# psc3_p8_ppca register map
Vendor: Infineon Technologies; Series: PSC3_P8; File version: 1.0
CPU: CM33 r0p1, little endian, MPU, FPU, VTOR, 3 interrupt priority bits
Registers are 32-bit, read-write, reset 0x0 unless marked. A register's access mark holds for its fields unless they carry their own. Offsets are from the block's base; [hi:lo] are bit positions; lines under a group give offsets from that group; {n}, {i} and the like mark numbered series; 'fields as' and 'values as' point back to an identical list.

## MXAES
Base 0x68270000
0x00 UNMASKED_USER_RANGE group — AES command and configuration registers
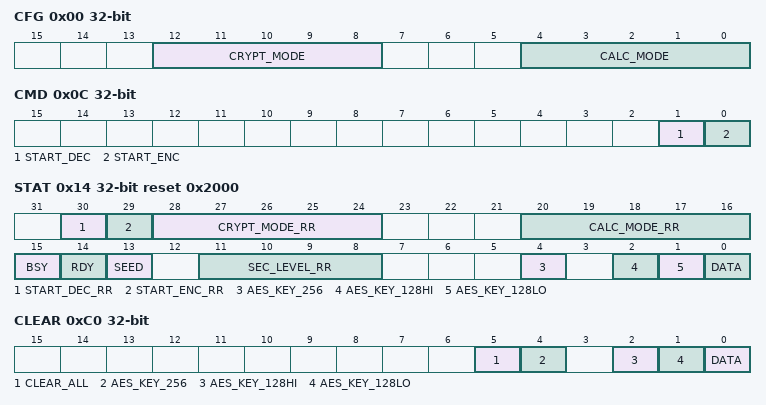
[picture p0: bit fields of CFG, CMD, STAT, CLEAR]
  0x00 CFG — AES configuration register
    [12:8] CRYPT_MODE — Cryptographic mode
      0=NOMODE (N/A); 16=AES128LO (N/A); 19=AES128HI (N/A); 22=AES256 (N/A)
    [4:0] CALC_MODE — Mode of AES calculation
      0=NOMODE (N/A); 3=CIPHER (N/A)
  0x0C CMD — AES command register
    [1] START_DEC — Launch an AES decryption operation
      0=NDEC (N/A); 1=DEC (N/A)
    [0] START_ENC — Launch an AES encryption operation
      0=NENC (N/A); 1=ENC (N/A)
  0x14 STAT ro reset 0x2000 — AES status register
    [30] START_DEC_RR — AES START_DEC reread bit
    [29] START_ENC_RR — AES START_ENC reread bit
    [28:24] CRYPT_MODE_RR — AES CRYPT_MODE reread bits
    [20:16] CALC_MODE_RR — AES CALC_MODE reread bits
    [15] BSY — Busy flag
      0=NBSY (N/A); 1=BSY (N/A)
    [14] RDY — Ready flag
      0=AES_NRDY (N/A); 1=AES_RDY (N/A)
    [13] SEED — Seeding status bit
      1=SEED (N/A); 0=NO_SEED (N/A)
    [11:8] SEC_LEVEL_RR — SEC_LEVEL reread bits
    [4] AES_KEY_256 — AES 256 Key valid
      0=A2IV (N/A); 1=A2V (N/A)
    [2] AES_KEY_128HI — AES 128 High key valid
      0=AHIV (N/A); 1=AHV (N/A)
    [1] AES_KEY_128LO — AES 128 Low key valid
      0=ALIV (N/A); 1=ALV (N/A)
    [0] DATA — AES data valid
      0=DNV (N/A); 1=DV (N/A)
  0x60 CFG_2 — AES configuration register 2
    [3:0] SEC_LEVEL — Security level
  0x80 INTR — AES interrupt cause register
    [0] CALC_FINISHED — Interrupt calculation finished
      1=CLEAR (N/A); 0=CLEARED (N/A)
  0x84 INTR_SET — AES interrupt set register
    [0] CALC_FINISHED — Write with '1' to set corresponding bit in interrupt request register.
  0x8C INTR_MASK — AES interrupt mask register
    [0] CALC_FINISHED — Mask bit for corresponding bit in interrupt request register.
  0x90 INTR_MASKED ro — AES masked interrupt register
    [0] CALC_FINISHED — Logical and of corresponding request and mask bits.
  0xC0 CLEAR wo — AES clear register
    [5] CLEAR_ALL — Clear all SFRs and AES internal registers
      0=NCLR (N/A); 1=CLR (N/A)
    [4] AES_KEY_256 — Clear AES 256 Key
      1=CLR (N/A); 0=NCLR (N/A)
    [2] AES_KEY_128HI — Clear AES 128 High Key
      0=NCLR (N/A); 1=CLR (N/A)
    [1] AES_KEY_128LO — Clear AES 128 Low Key
      0=NCLR (N/A); 1=CLR (N/A)
    [0] DATA — Clear data
      0=NCLR (N/A); 1=CLR (N/A)
  0xDC BUS_COUNTER — AES Bus counter register
    [7:0] CTR — Key and data write counter
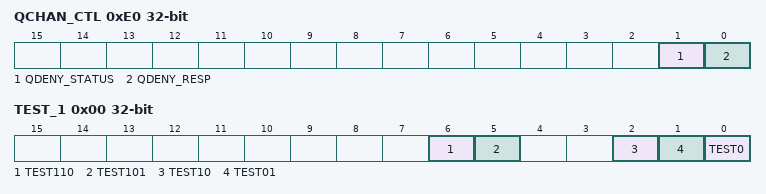
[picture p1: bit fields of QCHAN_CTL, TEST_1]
  0xE0 QCHAN_CTL — AES Q-channel control register
    [1] QDENY_STATUS — Q-Channel QDENY Status. This status bit allows dynamic debug when a qdeny occurs.
      0=NODENY (No quiescence request was denied); 1=DENIED (A quiescence request was denied)
    [0] QDENY_RESP — Q-Channel QDENY Response Policy. This policy bit provides SW flexibility to determine whether to assert qdeny or qaccept when qreq is asserted but the IP is not quiescent. Note: The RNG always accepts the request with a clock cycle delay. That is, the register does not have any effect and is a dummy register.
      1=ACCEPT (A quiescence request is always accepted); 0=DENY (A quiescence request may be denied)
0x800 UNMASKED_INTERNAL_RANGE group — AES data registers (x for index of shares; y for index of word)
  0x00 TEST_1 — AES test register 1
    [6] TEST110 — AES test bit 6
    [5] TEST101 — AES test bit 5
    [2] TEST10 — AES test bit 2
    [1] TEST01 — AES test bit 1
    [0] TEST0 — AES test bit 0
0x1000 MASKED_USER_RANGE group — AES key shares
  0x00 SEED_U wo — AES user seeding register
    [31:0] PRNG_SEED — Seed for internal masking
  {0x100+0xC*j} KEY_0_{j} wo (j=0..7) — AES share 0 word {j} key register
    [31:0] KEY — AES key_x_y register (x for index of shares; y for index of word)
  {0x160+0xC*j} KEY_1_{j} wo (j=0..6) — AES share 1 word {j} key register
    fields as MASKED_USER_RANGE.KEY_0_0
  0x1B4 KEY_1_7 wo — AES share 1 word 7 data register
    fields as MASKED_USER_RANGE.KEY_0_0
  {0x400+0xC*j} DATA_0_{j} (j=0..3) — AES share 0 word {j} data register
    [31:0] DATA — AES data_x_y register (x for index of shares; y for index of word)
  {0x430+0xC*j} DATA_1_{j} (j=0..3) — AES share 1 word {j} data register
    fields as MASKED_USER_RANGE.DATA_0_0
  {0x490+0xC*j} DATA_RR_0_{j} ro (j=0..3) — AES share 0 word {j} data reread register
    [31:0] DATA — AES data reread register (data_rr_x_y: x for index of shares; y for index of word)
  {0x4C0+0xC*j} DATA_RR_1_{j} ro (j=0..3) — AES share 1 word {j} data reread register
    fields as MASKED_USER_RANGE.DATA_RR_0_0
0x1800 MASKED_INTERNAL_RANGE group — AES Internal registers
  0x00 TEST_2 wo — AES second test register
    [31:0] TEST — Test bits

## Notices in the file
(c) (2016-2025), Cypress Semiconductor Corporation (an Infineon company)
or an affiliate of Cypress Semiconductor Corporation.
SPDX-License-Identifier: Apache-2.0
Licensed under the Apache License, Version 2.0 (the "License");
you may not use this file except in compliance with the License.
You may obtain a copy of the License at
http://www.apache.org/licenses/LICENSE-2.0
Unless required by applicable law or agreed to in writing, software
distributed under the License is distributed on an "AS IS" BASIS,
WITHOUT WARRANTIES OR CONDITIONS OF ANY KIND, either express or implied.
See the License for the specific language governing permissions and
limitations under the License.
